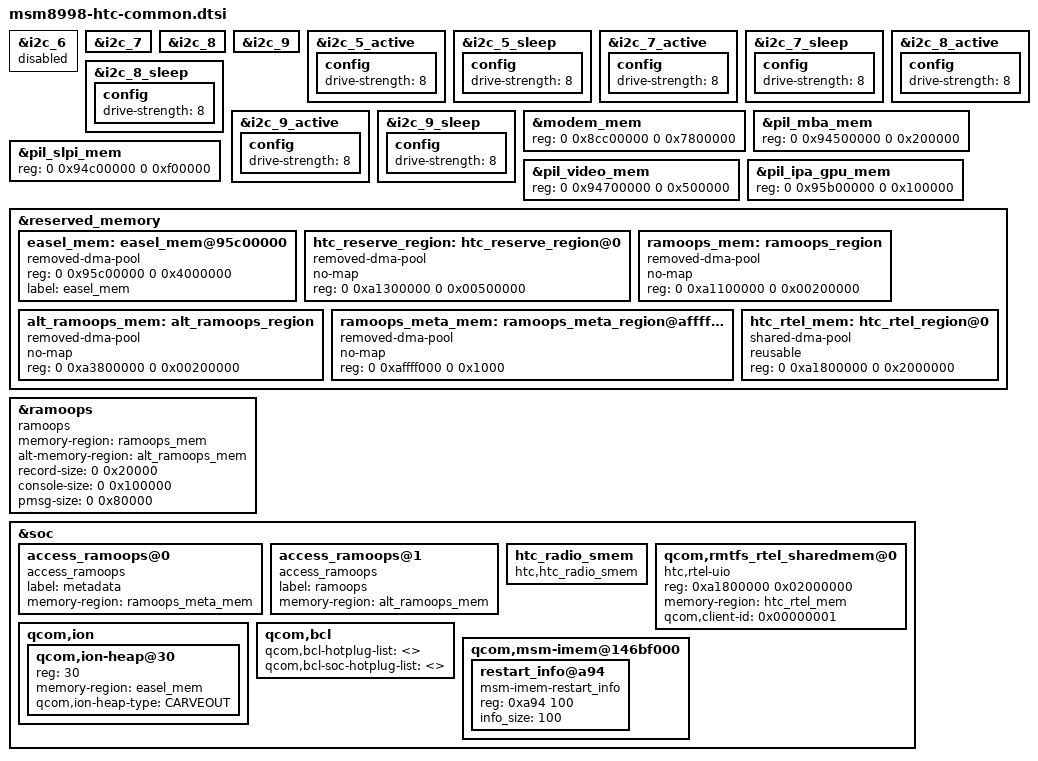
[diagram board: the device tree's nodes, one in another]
/*
 * msm8998-htc-common: common configs of msm8998 HTC projects
 */

#include "msm8998-key-muskie.dtsi"
#include "msm8998-audio-muskie.dtsi"

&i2c_6 {
	status = "disabled";
};

&i2c_7 {
	status = "okay";
};

&i2c_8 {
	status = "okay";
};

&i2c_9 {
	status = "okay";
};

&i2c_5_active {
	config {
		drive-strength = <8>;
	};
};
&i2c_5_sleep {
	config {
		drive-strength = <8>;
	};
};

&i2c_7_active {
	config {
		drive-strength = <8>;
	};
};
&i2c_7_sleep {
	config {
		drive-strength = <8>;
	};
};

&i2c_8_active {
	config {
		drive-strength = <8>;
	};
};
&i2c_8_sleep {
	config {
		drive-strength = <8>;
	};
};

&i2c_9_active {
	config {
		drive-strength = <8>;
	};
};
&i2c_9_sleep {
	config {
		drive-strength = <8>;
	};
};

&modem_mem {
	/* qct original reg = <0 0x8cc00000 0 0x7000000>; */
	reg = <0 0x8cc00000 0 0x7800000>;
};

&pil_mba_mem {
	/* qct original reg = <0 0x94100000 0 0x200000>; */
	reg = <0 0x94500000 0 0x200000>;
};

&pil_video_mem {
	/* qct original reg = <0 0x93c00000 0 0x500000>; */
	reg = <0 0x94700000 0 0x500000>;
};

&pil_slpi_mem {
	/* qct original reg = <0 0x94100000 0 0xf00000>; */
	reg = <0 0x94c00000 0 0xf00000>;
};

&pil_ipa_gpu_mem {
	/* qct original reg = <0 0x95000000 0 0x100000>; */
	reg = <0 0x95b00000 0 0x100000>;
};

&reserved_memory {

	easel_mem: easel_mem@95c00000 {
		compatible = "removed-dma-pool";
		reg = <0 0x95c00000 0 0x4000000>;
		label = "easel_mem";
	};

	htc_reserve_region: htc_reserve_region@0 {
		compatible = "removed-dma-pool";
		no-map;
		reg = <0 0xa1300000 0 0x00500000>;
	};

	ramoops_mem: ramoops_region {
		compatible = "removed-dma-pool";
		no-map;
		reg = <0 0xa1100000 0 0x00200000>;
	};

	alt_ramoops_mem: alt_ramoops_region {
		compatible = "removed-dma-pool";
		no-map;
		reg = <0 0xa3800000 0 0x00200000>;
	};

	ramoops_meta_mem: ramoops_meta_region@affff000 {
		compatible = "removed-dma-pool";
		no-map;
		reg = <0 0xaffff000 0 0x1000>;
	};

	htc_rtel_mem: htc_rtel_region@0 {
		compatible = "shared-dma-pool";
		reusable;
		reg = <0 0xa1800000 0 0x2000000>; /* 32 MB */
	};
};

&ramoops {
	compatible = "ramoops";
	memory-region = <&ramoops_mem>;
	alt-memory-region = <&alt_ramoops_mem>;
	record-size = <0 0x20000>; /* 128 KB */
	console-size = <0 0x100000>; /* 1024 KB */
	pmsg-size = <0 0x80000>; /* 512 KB */
};

&soc {
	access_ramoops@0 {
		compatible = "access_ramoops";
		label = "metadata";
		memory-region = <&ramoops_meta_mem>;
	};

	access_ramoops@1 {
		compatible = "access_ramoops";
		label = "ramoops";
		memory-region = <&alt_ramoops_mem>;
	};


	htc_radio_smem {
		compatible = "htc,htc_radio_smem";
	};

	qcom,rmtfs_rtel_sharedmem@0 {
		compatible = "htc,rtel-uio";
		reg = <0xa1800000 0x02000000>;
		memory-region = <&htc_rtel_mem>;
		reg-names = "rtel";
		qcom,client-id = <0x00000001>;
	};

	qcom,ion {
		qcom,ion-heap@30 {
			reg = <30>;
			memory-region = <&easel_mem>;
			qcom,ion-heap-type = "CARVEOUT";
		};
	};

	qcom,bcl {
		qcom,bcl-hotplug-list = <>;
		qcom,bcl-soc-hotplug-list = <>;
	};

	qcom,msm-imem@146bf000 {
		restart_info@a94 {
			compatible = "msm-imem-restart_info";
			reg = <0xa94 100>;
			info_size = <100>;
		};
	};
};
